AUTOSAR XML (schema 3-2-1)
package /test/test_swc
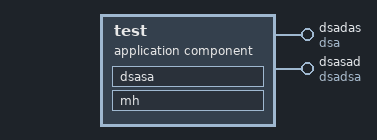
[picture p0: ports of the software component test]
  application software component type test
    provide port dsadas: provided-interface=dsa
      provided-com-specs:
        data-element=dsa, alive-timeout=60.0
        data-element=ds, alive-timeout=60.0
        data-element=fg, alive-timeout=60.0
    provide port dsasad: provided-interface=dsadsa
      provided-com-specs:
        data-element=s, alive-timeout=60.0
        data-element=d, alive-timeout=60.0
        data-element=f, alive-timeout=60.0
  internal behavior testBehavior: component=test
    runnable dsasa: can-be-invoked-concurrently=true
      data-read-access:
        data write accesss adsdsf: data-element=dsadas.dsa
        data write accesss gnhg: data-element=dsadas.dsa
        data write accesss fsdfds: data-element=dsadas.dsa
    runnable mh: can-be-invoked-concurrently=true
      data-read-access:
        data write accesss bgfbg: data-element=dsadas.dsa
        data write accesss bgfbgf: data-element=dsadas.dsa
        data write accesss aefqw: data-element=dsadas.dsa
  swc implementation testImplementation: behavior=testBehavior
